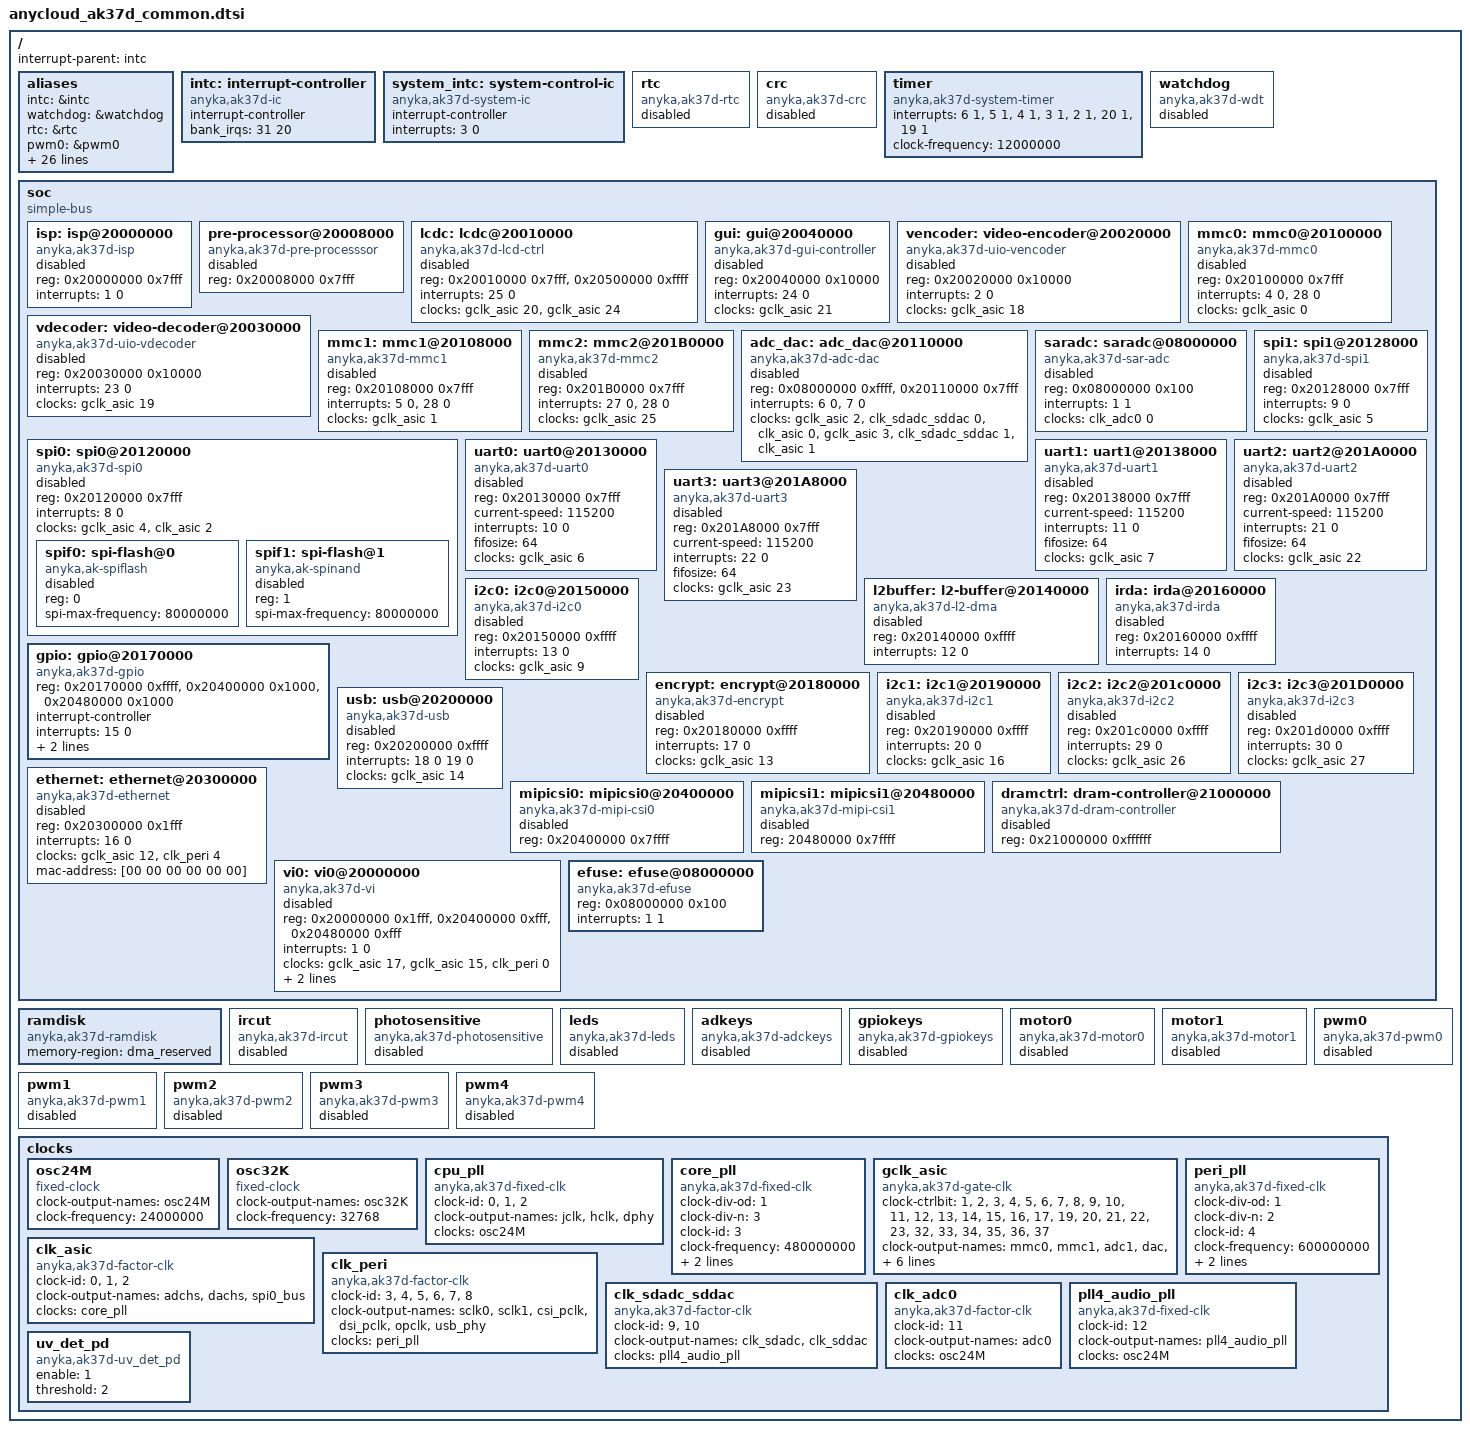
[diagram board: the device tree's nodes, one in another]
/*
 * AK37XXD & AK3918EV500 SoC
 *
 * Copyright (C) 2018 Anyka(Guangzhou) Microelectronics Technology Co., Ltd.
 *
 * Author: Feilong Dong <dong_feilong@anyka.com>
 *
 * This program is free software; you can redistribute it and/or modify
 * it under the terms of the GNU General Public License as published by
 * the Free Software Foundation; either version 2 of the License, or
 * (at your option) any later version.
 *
 * This program is distributed in the hope that it will be useful,
 * but WITHOUT ANY WARRANTY; without even the implied warranty of
 * MERCHANTABILITY or FITNESS FOR A PARTICULAR PURPOSE.  See the
 * GNU General Public License for more details.
 */
#include <dt-bindings/gpio/gpio.h>

/*
* snd-dev:
*   SND_CARD_DAC_PLAYBACK = 0
*   SND_CARD_ADC_CAPTURE = 1
*   SND_CARD_DAC_LOOPBACK = 2
*   SND_CARD_I2S0_SEND = 3
*   SND_CARD_I2S0_RECV = 4
*   SND_CARD_I2S0_LOOPBACK = 5
*   SND_CARD_I2S1_RECV = 6
*   SND_CARD_PDM_RECV = 7
* snd-type:
*   AK_PCM_DEV_PLAYBACK = 0
*   AK_PCM_DEV_CAPTURE = 1
*   AK_PCM_DEV_LOOPBACK = 2
* snd-idx:
*   for the sample snd-type, make diff idx to re-name them
* !!!Please notice this configration as same as the ak_pcm_def.h!!!
*/
#define SND_CARD_DAC_PLAYBACK   0
#define SND_CARD_ADC_CAPTURE    1
#define SND_CARD_DAC_LOOPBACK   2
#define SND_CARD_I2S0_SEND      3
#define SND_CARD_I2S0_RECV      4
#define SND_CARD_I2S0_LOOPBACK  5
#define SND_CARD_I2S1_RECV      6
#define SND_CARD_PDM_RECV       7

#define AK_PCM_DEV_PLAYBACK     0
#define AK_PCM_DEV_CAPTURE      1
#define AK_PCM_DEV_LOOPBACK     2

/ {
    #address-cells = <1>;
    #size-cells = <1>;

    interrupt-parent = <&intc>;

	aliases {
		intc = &intc;
		watchdog = &watchdog;
		rtc = &rtc;
		pwm0 = &pwm0;
		pwm1 = &pwm1;
		pwm2 = &pwm2;
		pwm3 = &pwm3;
		pwm4 = &pwm4;
		gpio = &gpio;
		uart0 = &uart0;
		uart1 = &uart1;
		uart2 = &uart2;
		uart3 = &uart3;
		spi0 = &spi0;
		spi1 = &spi1;
		mmc0 = &mmc0;
		mmc1 = &mmc1;
		mmc2 = &mmc2;
		i2c0 = &i2c0;
		i2c1 = &i2c1;
		i2c2 = &i2c2;
		motor0 = &motor0;
		motor1 = &motor1;
		mipicsi0 = &mipicsi0;
		mipicsi1 = &mipicsi1;
		usb = &usb;
		leds = &leds;
		adkeys = &adkeys;
		gpiokeys = &gpiokeys;		
		ethernet0 = &ethernet;
	};

    intc: interrupt-controller {
        compatible = "anyka,ak37d-ic";
        interrupt-controller;
        #interrupt-cells = <2>;
		bank_irqs = <31 20>;
    };

    system_intc: system-control-ic {
        compatible = "anyka,ak37d-system-ic";
        interrupt-controller;
	    interrupts = <3 0>;
    };

    rtc: rtc {
        compatible = "anyka,ak37d-rtc";
        status = "disable";
    };

    crc: crc {
        compatible = "anyka,ak37d-crc";
        status = "disable";
    };

    timer{
        compatible = "anyka,ak37d-system-timer";
        interrupts = <6 1>,
                     <5 1>,
                     <4 1>,
                     <3 1>,
                     <2 1>,
                     <20 1>,
                     <19 1>;
        clock-frequency = <12000000>;
        status = "okay";
    };

    watchdog: watchdog {
        compatible = "anyka,ak37d-wdt";
        status = "disable";
    };

	soc: soc {
		compatible = "simple-bus";
		#address-cells = <1>;
		#size-cells = <1>;
		ranges;

        isp: isp@20000000 {
            compatible = "anyka,ak37d-isp";
            reg = <0x20000000 0x7fff>;
            interrupts = <1 0>;
            status = "disable";
        };

        pre-processor@20008000 {
            compatible = "anyka,ak37d-pre-processsor";
            reg = <0x20008000 0x7fff>;
            status = "disable";
        };

        lcdc: lcdc@20010000 {
            compatible = "anyka,ak37d-lcd-ctrl";
            reg = <0x20010000 0x7fff>, /* lcd ctrl */
                  <0x20500000 0xffff>; /* dsi ctrl */
            interrupts = <25 0>;
            clocks = <&gclk_asic 20>, <&gclk_asic 24>;
            clock-names = "lcdc", "mipi_dsi";
		    status = "disable";
        };

		gui: gui@20040000 {
			compatible = "anyka,ak37d-gui-controller";
			reg = <0x20040000 0x10000>;
			interrupts = <24 0>;
			clocks = <&gclk_asic 21>;
			status = "disable";
		};

        vencoder: video-encoder@20020000 {
            compatible = "anyka,ak37d-uio-vencoder";
            reg = <0x20020000 0x10000>;
            interrupts = <2 0>;
            clocks = <&gclk_asic 18>;
            status = "disable";
        };

        vdecoder: video-decoder@20030000 {
            compatible = "anyka,ak37d-uio-vdecoder";
            reg = <0x20030000 0x10000>;
            interrupts = <23 0>;
            clocks = <&gclk_asic 19>;
            status = "disable";
        };

		mmc0: mmc0@20100000 {
            compatible = "anyka,ak37d-mmc0";
            reg = <0x20100000 0x7fff>;
            interrupts = <4 0>,<28 0>;
			clocks = <&gclk_asic 0>;
            status = "disable";
        };

        mmc1: mmc1@20108000 {
            compatible = "anyka,ak37d-mmc1";
            reg = <0x20108000 0x7fff>;
            interrupts = <5 0>, <28 0>;
			clocks = <&gclk_asic 1>;
            status = "disable";
        };

        mmc2: mmc2@201B0000 {
            compatible = "anyka,ak37d-mmc2";
            reg = <0x201B0000 0x7fff>;
            interrupts = <27 0>,<28 0>;
			clocks = <&gclk_asic 25>;
            status = "disable";
        };

        adc_dac: adc_dac@20110000 {
            compatible = "anyka,ak37d-adc-dac";
            reg = <0x08000000 0xffff>,
                <0x20110000 0x7fff>;
            interrupts = <6 0>,<7 0>;
            clocks =
            <&gclk_asic 2>,         //sdadc_gclk
            <&clk_sdadc_sddac 0>,   //sdadc_clk
            <&clk_asic 0>,          //sdadchs_clk
            <&gclk_asic 3>,         //sddac_gclk
            <&clk_sdadc_sddac 1>,   //sddac_clk
            <&clk_asic 1>;          //sddachs_clk

            clock-names =
            "sdadc_gclk",
            "sdadc_clk",
            "sdadchs_clk",
            "sddac_gclk",
            "sddac_clk",
            "sddachs_clk";
            status = "disable";
        };
        
        saradc: saradc@08000000 {
            compatible = "anyka,ak37d-sar-adc";
            reg = <0x08000000 0x100>;
            interrupts = <1 1>;
	        clocks = <&clk_adc0 0>;
            status = "disable";
        };
        
        spi0: spi0@20120000 {
            compatible = "anyka,ak37d-spi0";
            reg = <0x20120000 0x7fff>;
            interrupts = <8 0>;
            clocks = <&gclk_asic 4>, <&clk_asic 2>;
            clock-names = "spi0", "spi0_bus";

            #address-cells = <1>;
            #size-cells = <0>;
            status = "disable";

			spif0:spi-flash@0 {
			    compatible = "anyka,ak-spiflash";
				reg = <0>; /* Chip select 0 */
				spi-max-frequency = <80000000>;
				status = "disable";
				#address-cells = <1>;
            	#size-cells = <0>;
			};

			spif1:spi-flash@1 {
			   compatible = "anyka,ak-spinand";
			   reg = <1>; /* Chip select 1 */
			   spi-max-frequency = <80000000>;
			   ///status = "okay";
			   status = "disable";
			};
        };

        spi1: spi1@20128000 {
            compatible = "anyka,ak37d-spi1";
            reg = <0x20128000 0x7fff>;
            interrupts = <9 0>;
            clocks = <&gclk_asic 5>;

            #address-cells = <1>;
            #size-cells = <0>;
            status = "disable";
        };

        uart0: uart0@20130000 {
            compatible = "anyka,ak37d-uart0";
            reg = <0x20130000 0x7fff>;
            current-speed = <115200>;
            interrupts = <10 0>;
            fifosize = <64>;
            clocks = <&gclk_asic 6>;
            status = "disable";
        };

        uart1: uart1@20138000 {
            compatible = "anyka,ak37d-uart1";
            reg = <0x20138000 0x7fff>;
            current-speed = <115200>;
            interrupts = <11 0>;
            fifosize = <64>;
            clocks = <&gclk_asic 7>;
            status = "disable";
        };

        uart2: uart2@201A0000 {
            compatible = "anyka,ak37d-uart2";
            reg = <0x201A0000 0x7fff>;
            current-speed = <115200>;
            interrupts = <21 0>;
            fifosize = <64>;
            clocks = <&gclk_asic 22>;
            status = "disable";
        };

        uart3: uart3@201A8000 {
            compatible = "anyka,ak37d-uart3";
            reg = <0x201A8000 0x7fff>;
            current-speed = <115200>;
            interrupts = <22 0>;
            fifosize = <64>;
            clocks = <&gclk_asic 23>;
            status = "disable";
        };
        
        
        l2buffer: l2-buffer@20140000 {
            compatible = "anyka,ak37d-l2-dma";
            reg = <0x20140000 0xffff>;
            interrupts = <12 0>;
            status = "disable";
        };

        i2c0: i2c0@20150000 {
            compatible = "anyka,ak37d-i2c0";
            reg = <0x20150000 0xffff>;
            interrupts = <13 0>;
            clocks = <&gclk_asic 9>;

            status = "disable";
        };

        irda: irda@20160000 {
            compatible = "anyka,ak37d-irda";
            reg = <0x20160000 0xffff>;
            interrupts = <14 0>;
            status = "disable";
        };

        gpio: gpio@20170000 {
            compatible = "anyka,ak37d-gpio";
            reg = <0x20170000 0xffff>,
            <0x20400000 0x1000>,	/* mipi0 */
            <0x20480000 0x1000>;	/* mipi1 */

            interrupt-controller;
            #interrupt-cells = <2>;
            interrupts = <15 0>;
            clocks = <&gclk_asic 12>;

            gpio-controller;
            #gpio-cells = <2>;
            status = "okay";
        };

        encrypt: encrypt@20180000 {
            compatible = "anyka,ak37d-encrypt";
            reg = <0x20180000 0xffff>;
            interrupts = <17 0>;
            clocks = <&gclk_asic 13>;
            status = "disable";
        };

        i2c1: i2c1@20190000 {
            compatible = "anyka,ak37d-i2c1";
            reg = <0x20190000 0xffff>;
            interrupts = <20 0>;
            clocks = <&gclk_asic 16>;

            status = "disable";
        };
        
       i2c2: i2c2@201c0000 {
            compatible = "anyka,ak37d-i2c2";
            reg = <0x201c0000 0xffff>;
            interrupts = <29 0>;
            clocks = <&gclk_asic 26>;

            #address-cells = <1>;
	        #size-cells = <0>;
            status = "disable";
        };

        i2c3: i2c3@201D0000 {
            compatible = "anyka,ak37d-i2c3";
            reg = <0x201d0000 0xffff>;
            interrupts = <30 0>;
            clocks = <&gclk_asic 27>;
 
            #address-cells = <1>;
            #size-cells = <0>;
            status = "disable";
        };

        usb: usb@20200000 {
            compatible = "anyka,ak37d-usb";
            reg = <0x20200000 0xffff>;
            interrupts = <18 0
                          19 0>;
            clocks = <&gclk_asic 14>;
            status = "disable";
        };

        ethernet: ethernet@20300000 {
            compatible = "anyka,ak37d-ethernet";
            reg = <0x20300000 0x1fff>;
            interrupts = <16 0>;
            clock-names = "ethernet", "50M";
            clocks = <&gclk_asic 12>, <&clk_peri 4>;
			mac-address = [00 00 00 00 00 00];
            status = "disable";
        };

        mipicsi0: mipicsi0@20400000 {
            compatible = "anyka,ak37d-mipi-csi0";
            reg = <0x20400000 0x7ffff>;
            status = "disable";
        };

        mipicsi1: mipicsi1@20480000 {
            compatible = "anyka,ak37d-mipi-csi1";
            reg = <20480000 0x7ffff>;
            status = "disable";
        };

        dramctrl:dram-controller@21000000 {
            compatible = "anyka,ak37d-dram-controller";
            reg = <0x21000000 0xffffff>;
            status = "disable";
        };

        vi0: vi0@20000000 {
            compatible = "anyka,ak37d-vi";
            reg = <0x20000000 0x1fff>,	/*isp*/
                  <0x20400000 0xfff>,	/*mipicsi0*/
                  <0x20480000 0xfff>;	/*mipicsi1*/
            interrupts = <1 0>;
            clocks = <&gclk_asic 17>, <&gclk_asic 15>, <&clk_peri 0>;
            clock-names = "isp_clk", "mipi_csi_clk", "csi_sclk";
            clock-frequency_isp_clk = <24000000>;
			/*
				interface: 0-dvp, 1-mipi1lane, 2-mipi2lane
			*/
			interface = <0>;

		    status = "disable";
        };

		efuse: efuse@08000000 {
		   compatible = "anyka,ak37d-efuse";
		   reg = <0x08000000 0x100>;
		   interrupts = <1 1>;
		   status = "okay";
	   };

	};

    ramdisk:ramdisk{
        compatible = "anyka,ak37d-ramdisk";
        memory-region = <&dma_reserved>;
        status = "okay";
    };

	ircut: ircut {
		compatible = "anyka,ak37d-ircut";
		status = "disable";
	};

	photosensitive: photosensitive {
		compatible = "anyka,ak37d-photosensitive";
		status = "disable";
	};

	leds: leds {
		compatible = "anyka,ak37d-leds";
		status = "disable";
	};

	adkeys: adkeys {
		compatible = "anyka,ak37d-adckeys";
		status = "disable";
	};

	gpiokeys: gpiokeys {
		compatible = "anyka,ak37d-gpiokeys";
		status = "disable";
	};	
	
	motor0: motor0 {
		compatible = "anyka,ak37d-motor0";
		status = "disable";
	};

	motor1: motor1 {
		compatible = "anyka,ak37d-motor1";
		status = "disable";
	};

	pwm0: pwm0 {
		compatible = "anyka,ak37d-pwm0";
		status = "disable";
	};

	pwm1: pwm1 {
		compatible = "anyka,ak37d-pwm1";
		status = "disable";
	};

	pwm2: pwm2 {
		compatible = "anyka,ak37d-pwm2";
		status = "disable";
	};

	pwm3: pwm3 {
		compatible = "anyka,ak37d-pwm3";
		status = "disable";
	};

  pwm4: pwm4 {
		compatible = "anyka,ak37d-pwm4";
		status = "disable";
	};

    clocks {
        osc24M: osc24M {
            compatible = "fixed-clock";
            #clock-cells = <0>;
            clock-output-names = "osc24M";
            clock-frequency = <24000000>;
        };

        osc32K {
            compatible = "fixed-clock";
            #clock-cells = <0>;
            clock-output-names = "osc32K";
            clock-frequency = <32768>;
        };

        /* this clocks are configed in boot setting, can't be configed in kernel */
        /* this node is only for get cpu and mem clk in kernel */
        cpu_pll {
            compatible = "anyka,ak37d-fixed-clk";
            #clock-cells = <1>;
            clock-id = <0>, <1>, <2>;
        	clock-output-names = "jclk", "hclk", "dphy";
            clocks = <&osc24M>;
        };

        core_pll: core_pll {
            compatible = "anyka,ak37d-fixed-clk";
            #clock-cells = <0>;
            clock-div-od = <1>;
            clock-div-n = <3>;
            clock-id = <3>;
        	clock-frequency = <480000000>;
            clock-output-names = "core_pll";
            clocks = <&osc24M>;
        };

        gclk_asic:gclk_asic {
        	compatible = "anyka,ak37d-gate-clk";
        	#clock-cells = <1>;
            clock-ctrlbit = <1>, <2>, <3>,
                            <4>, <5>, <6>,
                            <7>, <8>, <9>,
                            <10>, <11>, <12>,
                            <13>, <14>, <15>,
                            <16>, <17>, <19>,
                            <20>, <21>, <22>,
                            <23>, <32>, <33>,
                            <34>, <35>, <36>,
                            <37>;
            clock-output-names = "mmc0", "mmc1", "adc1",
                                 "dac", "spi0", "spi1",
                                 "uart0", "uart1", "l2buffer",
                                 "i2c0", "irda", "gpio",
                                 "ethernet", "encrypt", "usb-otg",
                                 "mipi_csi", "i2c1", "isp",
                                 "vencoder","vdecoder","lcdc",
                                 "gui", "uart2", "uart3", 
                                 "mipi_dsi", "mmc2", "i2c2",
                                 "i2c3";
            clocks = <&core_pll>;
        };

        clk_asic: clk_asic {
        	compatible = "anyka,ak37d-factor-clk";
        	#clock-cells = <1>;
        	clock-id = <0>, <1>, <2>;
        	clock-output-names = "adchs", "dachs", "spi0_bus";
            clocks = <&core_pll>;
        };

    	/*config this clock in uboot*/
    	peri_pll: peri_pll {
            compatible = "anyka,ak37d-fixed-clk";
            #clock-cells = <0>;
            clock-div-od = <1>;
            clock-div-n = <2>;
        	clock-id = <4>;
        	clock-frequency = <600000000>;
        	clock-output-names = "peri_pll";
            clocks = <&osc24M>;
        };

        clk_peri: clk_peri {
        	compatible = "anyka,ak37d-factor-clk";
        	#clock-cells = <1>;
        	clock-id = <3>, <4>, <5>, <6>, <7>, <8>;
        	clock-output-names = "sclk0", "sclk1", "csi_pclk", "dsi_pclk", "opclk", "usb_phy";
        	clocks = <&peri_pll>;
        };
        clk_sdadc_sddac: clk_sdadc_sddac{
            compatible = "anyka,ak37d-factor-clk";
            #clock-cells = <1>;
            clock-id = <9>, <10>;
            clock-output-names = "clk_sdadc", "clk_sddac";
            clocks = <&pll4_audio_pll>;
        };

        clk_adc0: clk_adc0 {
        	compatible = "anyka,ak37d-factor-clk";
        	#clock-cells = <1>;
        	clock-id = <11>;
        	clock-output-names = "adc0";
        	clocks = <&osc24M>;
        };

        pll4_audio_pll: pll4_audio_pll {
            compatible = "anyka,ak37d-fixed-clk";
            #clock-cells = <0>;
            clock-id = <12>;
            clock-output-names = "pll4_audio_pll";
            clocks = <&osc24M>;
		};

       uv_det_pd:uv_det_pd {
            compatible = "anyka,ak37d-uv_det_pd";
            /*
            under_voltage_detection

            enable:
            0: disable under voltage detection
            1: enable under voltage detection

            threshold:
            0: reset when VDDIO drops below 2.48V,
                and the reset will be deasserted when VDDIO reaches 2.68V
            1: reset when VDDIO drops below 2.65V,
                and the reset will be deasserted when VDDIO reaches 2.86V
            2: reset when VDDIO drops below 2.72V,
                and the reset will be deasserted when VDDIO reaches 2.93V
            */
            enable = <1>;
            threshold = <2>;
            status = "okay";
        };
    };
};
